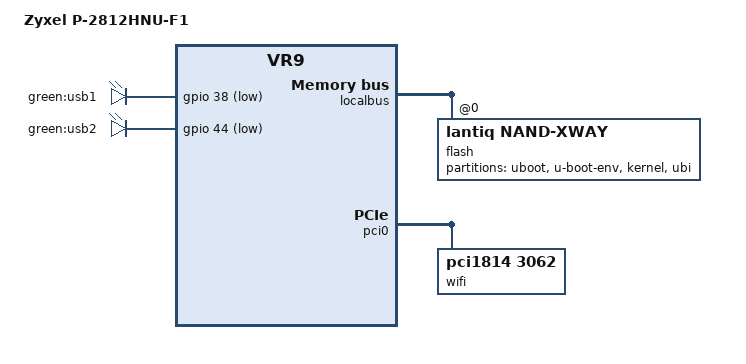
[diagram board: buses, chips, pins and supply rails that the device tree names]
#include "vr9_zyxel_p-2812hnu-fx.dtsi"

/ {
	compatible = "zyxel,p-2812hnu-f1", "zyxel,p-2812hnu", "lantiq,xway", "lantiq,vr9";
	model = "Zyxel P-2812HNU-F1";

	leds {
		usb1 {
			label = "green:usb1";
			gpios = <&gpio 38 GPIO_ACTIVE_LOW>;
			trigger-sources = <&ehci_port1>;
			linux,default-trigger = "usbport";
		};
		usb2 {
			label = "green:usb2";
			gpios = <&gpio 44 GPIO_ACTIVE_LOW>;
			trigger-sources = <&ehci_port2>;
			linux,default-trigger = "usbport";
		};
	};
};

&localbus {
	flash@0 {
		compatible = "lantiq,nand-xway";
		lantiq,cs = <1>;
		bank-width = <2>;
		reg = <0 0x0 0x2000000>;

		pinctrl-0 = <&nand_pins>, <&nand_cs1_pins>;
		pinctrl-names = "default";

		nand-use-soft-ecc-engine;

		partitions {
			compatible = "fixed-partitions";
			#address-cells = <1>;
			#size-cells = <1>;

			partition@0 {
				label = "uboot";
				reg = <0x00000 0x40000>;
			};
			partition@40000 {
				label = "u-boot-env";
				reg = <0x40000 0x20000>;

				nvmem-layout {
					compatible = "u-boot,env";
					env-size = <0x2000>;

					macaddr_uboot_ethaddr: ethaddr {
						#nvmem-cell-cells = <1>;
					};
				};
			};
			partition@60000 {
				label = "kernel";
				reg = <0x60000 0x500000>;
			};
			partition@560000 {
				label = "ubi";
				reg = <0x560000 0x7aa0000>;
			};
		};
	};
};

&pci0 {
	wifi@e,0 {
		compatible = "pci1814,3062";
		reg = <0x7000 0 0 0 0>;

		ralink,eeprom-data = <0x62300200 0x000c4330 0x62006230 0x14180180 0x00006230 0x14180000 0x01006aff 0x0c00ffff
				      0xffffffff 0xffffffff 0xffffffff 0xffffffff 0xffffffff 0x22082400 0xffff2801 0xffffd9fa
				      0xcc88ffff 0x0aff0000 0x03000000 0x0000ffff 0xffff0c0c 0x0c0d0d0d 0x0d0d0e0e 0x0e0e0e0e
				      0x0d0d0e0e 0x0f0f0f10 0x10111111 0x1111ffff 0xffffffff 0xffffffff 0xffffffff 0xffffffff
				      0xffffffff 0xffffffff 0xffffffff 0xffffffff 0xffffffff 0xffffffff 0xffffffff 0xffffffff
				      0xffffffff 0xffffffff 0xffffffff 0xffffffff 0xffffffff 0xffffffff 0xffffffff 0xffffffff
				      0xffffffff 0xffffffff 0xffffffff 0xffffffff 0xffffffff 0xffffffff 0xffffffff 0xffff6666
				      0x66666666 0x66666666 0x66666666 0x66666666 0xffffffff 0xffffffff 0xffffffff 0xffffffff
				      0xffffffff 0xffffffff 0xffffffff 0xffffffff 0xffffffff 0xffffffff 0xffffffff 0xffffffff
				      0xffffffff 0xffffffff 0xffffffff 0xffffffff 0xffffffff 0xffffffff 0xffffffff 0xffffffff
				      0xffffffff 0xffffffff 0xffffffff 0xffffffff 0xffffffff 0xffffffff 0xffffffff 0xffffffff
				      0xffffffff 0xffffffff 0xffffffff 0xffffffff 0xffffffff 0xffffffff 0xffffffff 0xffffffff
				      0xffffffff 0xffffffff 0xffffffff 0xffffffff 0xffffffff 0xffffffff 0xffffffff 0xffffffff
				      0xffffffff 0xffffffff 0xffffffff 0xffffffff 0xffffffff 0xffffffff 0xffffffff 0xffffffff
				      0xffffffff 0xffffffff 0xffffffff 0xffffffff 0xffffffff 0xffffffff 0xffffffff 0xffffffff
				      0xffffffff 0xffffffff 0xffffffff 0xffffffff 0xffffffff 0xffffffff 0xffffffff 0xffffffff>;

		nvmem-cells = <&macaddr_uboot_ethaddr 2>;
		nvmem-cell-names = "mac-address";
	};
};

&pcie0 {
	status = "disabled";
};
